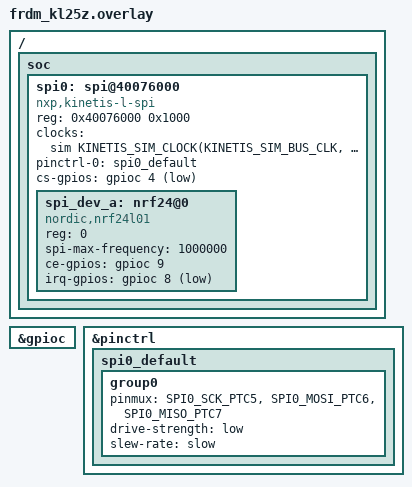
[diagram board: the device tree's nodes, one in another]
#include <nxp/kinetis/MKL25Z128VLK4-pinctrl.h>

&gpioc 
{
    status = "okay";
};

&pinctrl {
    spi0_default: spi0_default {
        group0 {
            pinmux = <SPI0_SCK_PTC5>,
                     <SPI0_MOSI_PTC6>,
                     <SPI0_MISO_PTC7>;
            drive-strength = "low";
            slew-rate = "slow";
        };
    };
};

/ {
    soc 
    {
        spi0: spi@40076000 
        {
            compatible = "nxp,kinetis-l-spi";
            reg = <0x40076000 0x1000>;
            
            clocks = <&sim KINETIS_SIM_CLOCK(KINETIS_SIM_BUS_CLK, 0x1034, 22)>;

            pinctrl-0 = <&spi0_default>;
            pinctrl-names = "default";

            #address-cells = <1>;
            #size-cells = <0>;
            status = "okay";

            cs-gpios = <&gpioc 4 GPIO_ACTIVE_LOW>;

            spi_dev_a: nrf24@0 {
                compatible = "nordic,nrf24l01";
                reg = <0>;
                spi-max-frequency = <1000000>;
                
                status = "okay";

                ce-gpios  = <&gpioc 9 GPIO_ACTIVE_HIGH>;
                irq-gpios = <&gpioc 8 (GPIO_ACTIVE_LOW | GPIO_PULL_UP)>;
            };
        };
    };
};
